# AU302NDF51 register map
File version: 1.0
Registers are 32-bit, access per field, reset 0x0 unless marked. A register's access mark holds for its fields unless they carry their own. Offsets are from the block's base; [hi:lo] are bit positions.

## SPI — Serial peripheral interface
Base 0x14200000
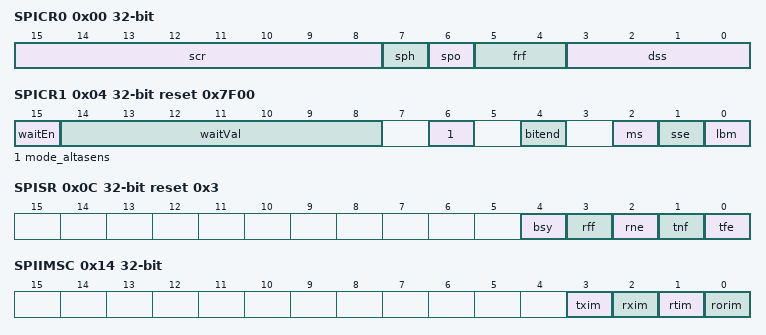
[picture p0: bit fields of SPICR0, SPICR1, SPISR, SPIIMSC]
0x00 SPICR0 rw — SPICR0 为控制寄存器 0。
  [15:8] scr — 串行时钟率，取值范围 0～255。scr 的值用来产生 SPI 发送和接收的比特率，公式为Fclk_spi/( cpsdvsr x (1+scr）)｡ cpsdvsr 是一个 2～254 之间的偶数，由寄存器 SPICPSR 配置。
  [7] sph — SPICLKOUT 相位，具体含义请参见 21.4接口时序章节的 SPI 帧格式。
  [6] spo — SPICLKOUT 极性，具体含义请参见 21.4接口时序章节的 SPI 帧格式。
  [5:4] frf — 帧格式选择。00：Motorola SPI 帧格式；01：TI 同步串行帧格式；10：National Microwire 帧格式；11：保留。
  [3:0] dss — 设置数据位宽。0x3：4bit；0x4：5bit；0x5：6bit；0x6：7bit；0x7：8bit；0x8：9bit；0x9：10bit；0xA：11bit；0xB：12bit；0xC：13bit；0xD：14bit；0xE：15bit；0xF：16bit；其他：保留。
0x04 SPICR1 reset 0x7F00 — SPICR1 为控制寄存器 1。
  [15] waitEn rw — 等待使能，当 SPICR1[sm]配置为 Master模式且 SPICR0[frf]配置为 National Microwire 帧格式时有效。0：不使能；1：使能。
  [14:8] waitVal rw — National Microwire 帧格式时，写和读之间的等待拍数。当 SPICR1[sm]配置为Master 模式且 waiten 为 1 并且帧格式为National Microwire 时有效。0x00：等待周期为 1 个工作时钟 clk_spi；0x01：等待周期为 2 个工作时钟 clk_spi；… 0x7F：等待周期为 128 个工作时钟clk_spi；其他：保留。
  [6] mode_altasens rw — 配置 SPI 片选产生的方式。0：片选信号由芯片逻辑根据所选时序自动产生；1：当采用 Motorola SPI 帧格式时，片选CS 信号由 SPI 使能信号控制，使能后，片选拉低，否则片选拉高。
  [4] bitend rw — 数据正反序控制位。0：数据顺序为 MSB 到 LSB；1：数据顺序为 LSB 到 MSB。
  [2] ms rw — 设置 Master 或者 Slave 模式，此位只能在SPI 被禁止时改变。0：Master 模式；1：Slave 模式。
  [1] sse rw — 设置 SPI 使能。0：不使能；1：使能。
  [0] lbm rw — 设置环回模式。0：正常的串行接口操作使能；1：发送串行移位寄存器的输出在内部连接到接收串行移位寄存器的输入上。
0x08 SPIDR rw — SPIDR 为数据寄存器。
  [15:0] data — 发送/接收 FIFO。读：接收 FIFO；写：发送 FIFO。如果数据比特数少于 16 则必须右对齐。发送逻辑将忽略高位未使用的比特位，接收逻辑则自动将数据右对齐。
0x0C SPISR reset 0x3 — SPISR为状态寄存器。
  [4] bsy rw — SPI 忙标记。0：空闲；1：忙。
  [3] rff rw — 接收 FIFO 是否已满。0：未满；1：已满。
  [2] rne rw — 接收 FIFO 是否未空。0：已空；1：未空。
  [1] tnf rw — 发送 FIFO 是否未满。0：已满；1：未满。
  [0] tfe rw — 发送 FIFO 是否已空。0：未空；1：已空。
0x10 SPICPSR — SPICPSR 为时钟分频寄存器。
  [7:0] CPSDVSR rw — 时钟分频因子。此值必须是 2～254 之间的偶数，取决于输入时钟 SPI_CLK 的频率。最低位读作“0”。
0x14 SPIIMSC — SPIIMSC为中断屏蔽寄存器
  [3] txim rw — 发送 FIFO 中断屏蔽。0：发送 FIFO 中断被屏蔽；1：发送 FIFO 中断未被屏蔽。
  [2] rxim rw — 接收 FIFO 中断屏蔽。0：接收 FIFO 中断被屏蔽；1：接收 FIFO 中断未被屏蔽。
  [1] rtim rw — 接收超时中断。0：接收超时中断屏蔽；1：接收超时中断不屏蔽。
  [0] rorim rw — 接收溢出中断屏蔽。0：接收 FIFO 溢出中断屏蔽；1：接收 FIFO 溢出中断不屏蔽。值为“1”时使能硬件流控功能，即接收FIFO 满后 SPI 停止发送数据。
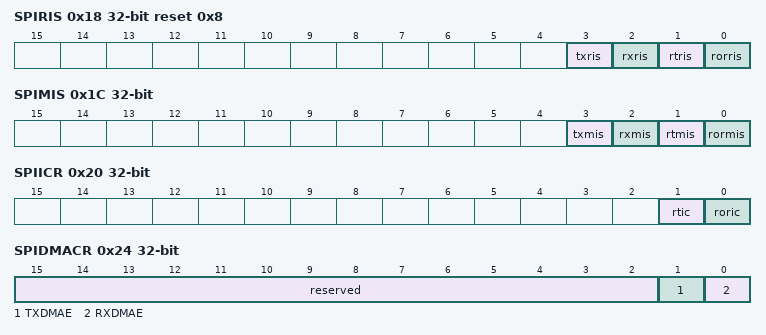
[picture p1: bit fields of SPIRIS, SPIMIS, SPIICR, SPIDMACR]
0x18 SPIRIS ro reset 0x8 — SPIRIS 为原始中断状态寄存器。值“0”表示无中断，值“1”表示有中断。
  [3] txris — 发送 FIFO 中断的原始中断状态。0：大于 SPITXFIFOCR[txintsize]位域中配置的中断水线；1：等于或小于 SPITXFIFOCR[txintsize]位域中配置的中断水线。
  [2] rxris — 接收 FIFO 中断的原始中断状态。0：小于 SPIRXFIFOCR[rxintsize]位域中配置的中断水线。1：等于或大于 SPIRXFIFOCR[rxintsize]位域中配置的中断水线。
  [1] rtris — 接收超时中断的原始中断状态。当接收FIFO 非空且没有被读取，超过 64 个 SPI工作时钟周期时，此位域置 1。对SPIICR[rtic]位域写 1，可清除此位域。
  [0] rorris — 接收溢出中断的原始中断状态。当接收FIFO 已满且额外的数据被接收时，发生溢出中断，此位域置 1。对 SPIICR[roric]位域写 1，可清除此位域。
0x1C SPIMIS ro — SPIMIS 为屏蔽后中断状态寄存器。值“0”表示无中断，值“1”表示有中断。
  [3] txmis — 发送 FIFO 中断屏蔽后的状态。
  [2] rxmis — 接收 FIFO 中断屏蔽后的状态。
  [1] rtmis — 接收超时中断屏蔽后的状态。
  [0] rormis — 接收溢出中断屏蔽后的状态。
0x20 SPIICR — SPIICR 为中断清除寄存器。写“1”清除中断，写“0”无影响。
  [1] rtic wo — 清除接收超时中断。
  [0] roric wo — 清除接收溢出中断。
0x24 SPIDMACR — SPIDMACR 为 DMA 控制寄存器。
  [15:2] reserved ro — 保留。
  [1] TXDMAE rw — DMA 发送 FIFO 使能寄存器。0：禁止；1：使能。
  [0] RXDMAE rw — DMA 接收 FIFO 使能寄存器。0：禁止；1：使能。
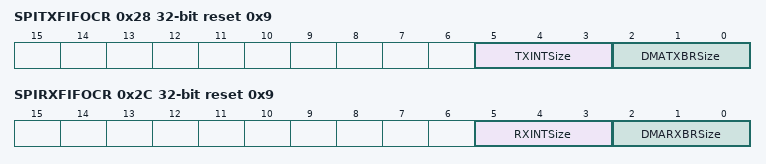
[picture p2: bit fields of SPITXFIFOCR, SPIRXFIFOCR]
0x28 SPITXFIFOCR reset 0x9 — SPITXFIFOCR 为发送 FIFO 控制寄存器。
  [5:3] TXINTSize rw — 配置发送 FIFO 请求中断的水线。即，发送 FIFO 中数据数目小于或等于 txintsize所配置的字数时，txris 有效。000：1；001：4；010：8；011：16；100：32；101：64；110：128；111：128。
  [2:0] DMATXBRSize rw — 配置发送 FIFO 请求 DMA 进行 burst 传输的水线。即，发送 FIFO 中数据数目小于或等于（256 - dmatxbrsize）所配置的字数时，DMATXBREQ 有效，此处字长是16 位。000：1；001：4；010：8；011：16；100：32；101：64；110：64；111：64。
0x2C SPIRXFIFOCR reset 0x9 — SPIRXFIFOCR 为接收 FIFO 控制寄存器。
  [5:3] RXINTSize rw — 配置接收 FIFO 请求中断的水线。即，接收 FIFO 中数据数目大于或等于（256 -rxintsize）所配置的字数时，rxris 有效，此处字长是 16 位。000：1；001：4；010：8；011：16；100：32；101：64；110：128；111：192。
  [2:0] DMARXBRSize rw — 配置接收 FIFO 请求 DMA 进行 burst 传输的水线。即，接收 FIFO 中数据数目大于或等于 dmarxbrsize 所配置的字数时，DMARXBREQ 有效。000：1；001：4；010：8；011：16；100：32；101：64；110：96；111：128。
0x100 SPICSNSEL — SPICSNSEL 为 SPI 片选选择寄存器。
  [0] spi_csn_sel rw — SPI 片选选择。0：片选 0；1：片选 1。
